# CC2753 register map
File version: 1.0
CPU: CM0+ r0p4, little endian, no MPU, no FPU, VTOR, 3 interrupt priority bits
Registers are 32-bit, read-write, reset 0x0 unless marked. A register's access mark holds for its fields unless they carry their own. Offsets are from the block's base; [hi:lo] are bit positions; {n}, {i} and the like mark numbered series; 'fields as' and 'values as' point back to an identical list.

## RTC — ULL Real Time Clock module RTC includes 2 channels. - Channel 0 is a compare channel - Channel 1 is a capture channel
Base 0x40002000
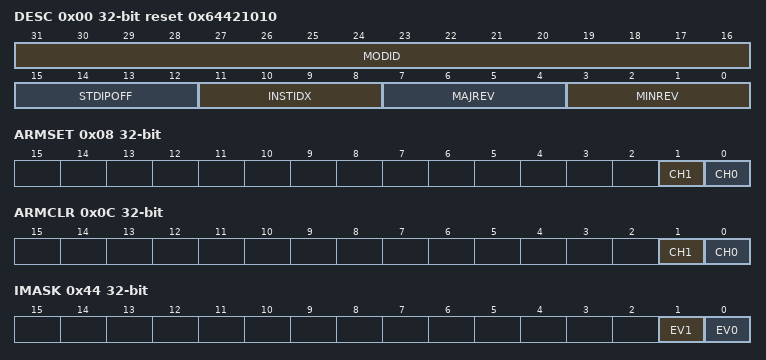
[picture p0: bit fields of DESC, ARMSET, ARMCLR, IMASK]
0x00 DESC ro reset 0x64421010 — Description Register. This register provides IP module ID, revision information, instance index and standard MMR registers offset.
  [31:16] MODID — Module identifier used to uniquely identify this IP.
  [15:12] STDIPOFF — Standard IP MMR block offset. Standard IP MMRs are the set of from aggregated IRQ registers till DTB. 0: Standard IP MMRs do not exist 0x1-0xF: Standard IP MMRs begin at offset of (64*STDIPOFF from the base IP address)
  [11:8] INSTIDX — IP Instance ID number. If multiple instances of IP exist in the device, this field can identify the instance number (0-15).
  [7:4] MAJREV — Major revision of IP (0-15).
  [3:0] MINREV — Minor revision of IP (0-15).
0x04 CTL — RTC Control register. This register controls resetting the of RTC counter
  [0] RST wo — RTC counter reset. Writing 1 to this bit will reset the RTC counter, and cause it to resume counting from 0x0
    1=CLR (Reset the timer.); 0=NOEFF (No effect)
0x08 ARMSET — RTC channel mode set register. Read to each bit field of this register provides the current channel mode. - Read of 1'b0 indicates the channel is unarmed. - Read of 1'b1 indicates the channel is either in capture or compare mode. A write to each bitfield of this register the following effect: - Write of 1'b0 has no effect on channel mode. - Write of 1'b1 has no effect on the compare channel. While write of 1'b1 for capture channel will arm it in capture mode if it is disabled.
  [1] CH1 — Arming Channel 1 for capture operation.
    1=SET (Enable the Channel 1 for capture operation); 0=NOEFF (No effect on the channel)
  [0] CH0 — No effect on arming the channel. Read will give the status of the Channel 0.
    1=SET (No effect on the compare channel); 0=NOEFF (No effect on the channel)
0x0C ARMCLR — RTC channel mode clear register. Read to each bit field of this register provides the current channel mode. - Read of 1'b0 indicates the channel is unarmed. - Read of 1'b1 indicates the channel is either in capture or compare mode. A write to each bitfield of this register the following effect: - Write of 1'b0 has no effect on channel mode. - Write of 1'b1 for capture/compare channel will disarm it without triggering event unless a compare/capture event happens in the same cycle.
  [1] CH1 — Disarming Channel 1
    1=CLR (Set channel in UNARMED state without triggering event unless a capture event happens in the same cycle); 0=NOEFF (No effect on the channel)
  [0] CH0 — Disarming Channel 0
    1=CLR (Set channel in UNARMED state without triggering event unless a compare event happens in the same cycle); 0=NOEFF (No effect on the channel)
0x10 TIME250N ro — RTC Time value register. 32-bit unsigned integer representing [29:-2] time slice of the real time clock counter. The counter runs on LFCLK. This field has a resolution of 250ns, and range of about 17.8 minutes.
  [31:0] VAL — [29:-2] slice of RTC TIME[50:-2]. Slice has an LSB weight of 250 ns and modular range 17m 53.74182002 s. RTC.TIME is updated every LF clock modulo by a fixed or measured LFINC value and will thus on average update only every ~30.5 us. SYSTIM.TIME is synchronized to RTC TIME[31:-2] and is updated every 250 ns if better resolution is needed (in addition to having a much shorter access time of 1-2 cycles instead of 22-26 cycles for RTC.TIMEx).
0x14 TIME1U ro — RTC Time value register. 32-bit unsigned integer representing [31:0] time slice of the real time clock counter. The counter runs on LFCLK. This field has a resolution of 1us, and range of about 1.19 hours.
  [31:0] VAL — [31:0] slice of RTC TIME[50:-2]. Slice has an LSB weight of 1 us and modular range 1h 11m 34.967296s. RTC.TIME is updated every LF clock modulo by a fixed or measured LFINC value and will thus on average update only every ~30.5 us. SYSTIM.TIME is synchronized to RTC TIME[31:-2] and is updated every 250 ns if better resolution is needed (in addition to having a much shorter access time of 1-2 cycles instead of 22-26 cycles for RTC.TIMEx).
0x18 TIME8U ro — RTC Time value register. 32-bit unsigned integer representing [34:3] time slice of the real time clock counter. The counter runs on LFCLK. This field has a resolution of 8us, and range of about 9.5 hours.
  [31:0] VAL — [34:3] slice of RTC TIME[50:-2]. Slice has an LSB weight of 8 us and modular range 9h 32m 39.73836s. RTC.TIME is updated every LF clock modulo by a fixed or measured LFINC value and will thus on average update only every ~30.5 us. SYSTIM.TIME is synchronized to RTC TIME[31:-2] and is updated every 250 ns if better resolution is needed (in addition to having a much shorter access time of 1-2 cycles instead of 22-26 cycles for RTC.TIMEx).
0x1C TIME524M ro — RTC time value register. 32-bit unsigned integer representing [50:19] time slice of the real time clock counter. This field has a resolution of about 0.5s and a range of about 71.4 years.
  [31:0] VAL — [50:19] slice of RTC TIME[50:-2]. Slice has an LSB weight of 0.524288s and modular range of approximately 71 years 147 days 11h 56m 53s. RTC.TIME is updated every LF clock modulo by a fixed or measured LFINC value and will thus on average update only every ~30.5 us. SYSTIM.TIME is synchronized to RTC TIME[31:-2] and is updated every 250 ns if better resolution is needed (in addition to having a much shorter access time of 1-2 cycles instead of 22-26 cycles for RTC.TIMEx).
0x20 CH0CC250N — Channel 0 compare value with 250ns resolution. A read to this register returns the value {CH0CC8U[29:3], 5b’0} A write to this register arms the channel in compare mode. Event would occur at the same time +/ Tlfclk/2 on the RTC as if it was written to SYSTIM.
  [31:0] VAL — RTC Channel 0 compare value. This value is compared against TIME8U.VAL. A Channel 0 event is generated when TIME8U.VAL value reaches or exceeds this compare value.
0x24 CH0CC1U — Channel 0 compare value with 1us resolution. A read to this register returns the value {CH0CC8U[31:3], 3b’0} A write to this register arms the channel in compare mode. Event would occur at the same time +/ Tlfclk/2 on the RTC as if it was written to SYSTIM.
  fields as CH0CC250N
0x28 CH0CC8U — Channel 0 compare value. A write to this register automatically enables the channel to trigger an event when RTC timer reaches the programmed value or if the programmed value is 1 sec in the past.
  fields as CH0CC250N
0x38 CH1CC8U ro — Channel 1 capture value. This register captures the RTC time slice [34:3] on each selected edge of the capture event when the ARMSET.CH1 = 1.
  [20:0] VAL — TIME8U.VAL captured value at the last selected edge of capture event.
0x3C CH1CFG — Channel 1 configuration register. This register can be used to select the capture edge for generating the capture event.
  [0] EDGE — Edge detect configuration for capture source
    1=FALL (Falling Edge.); 0=RISE (Rising Edge.)
0x44 IMASK — Interrupt Mask. If a bit is set, then corresponding interrupt is un-masked. Un-masking the interrupt causes the raw interrupt to be visible in IIDX, as well as MIS.
  [1] EV1 — Channel 1 Event Interrupt Mask.
    1=EN (Enable Interrrupt Mask); 0=DIS (Clear Interrupt Mask)
  [0] EV0 — Channel 0 Event Interrupt Mask.
    1=EN (Enable Interrrupt Mask); 0=DIS (Disable Interrupt Mask)
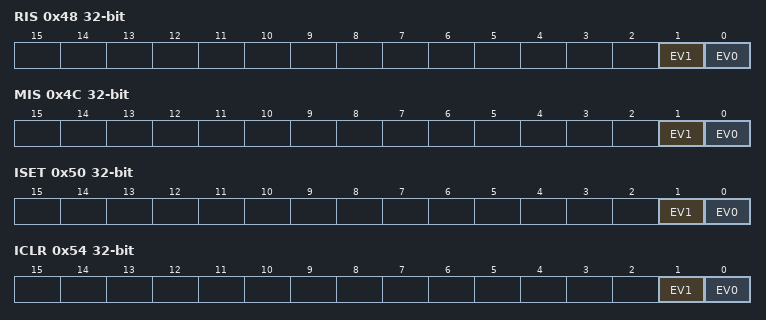
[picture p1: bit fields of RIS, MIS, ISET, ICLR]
0x48 RIS ro — Interrupt mask. This register selects interrupt sources which are allowed to pass from RIS to MIS when the corresponding bit-fields are set to 1.
  [1] EV1 — Raw interrupt status for Channel 1 event. This bit is set to 1 when a capture event is received on Channel 1. This bit will be cleared when the bit in ICLR.EV1 is set to 1 or when the captured time value is read from the CH1CC8U register.
    1=SET (Interrupt occured); 0=CLR (Interrupt did not occur)
  [0] EV0 — Raw interrupt status for Channel 0 event. This bit is set to 1 when a compare event occurs on Channel 0. This bit will be cleared. When the corresponding bit in ICLR.EV0 is set to 1. Or when a new compare value is written in CH0CC8U register
    1=SET (Interrupt occured); 0=CLR (Interrupt did not occur)
0x4C MIS ro — Masked interrupt status. This register is simply a bitwise AND of the contents of IMASK and RIS.*] registers. A flag set in this register can be cleared by writing 1 to the corresponding ICLR register bit.
  [1] EV1 — Masked interrupt status for channel 1 event.
    1=SET (Interrupt occured); 0=CLR (Interrupt did not occur)
  [0] EV0 — Masked interrupt status for channel 0 event.
    1=SET (Interrupt occured); 0=CLR (Interrupt did not occur)
0x50 ISET wo — Interrupt set register. This register can used by software for diagnostics and safety checking purposes. Writing a 1 to a bit in this register will set the event and the corresponding RIS bit also gets set. If the corresponding IMASK bit is set, then the corresponding MIS register bit also gets set.
  [1] EV1 — Set Channel 1 event Interrupt.
    1=SET (Set interrupt); 0=NO_EFFECT (Writing 0 has no effect)
  [0] EV0 — Set Channel 0 event Interrupt.
    1=SET (Set interrupt); 0=NO_EFFECT (Writing 0 has no effect)
0x54 ICLR wo — Interrupt clear register. This register allows software to clear interrupts. Writing a 1 to a bit in this register will clear the event and the corresponding RIS bit also gets cleared. If the corresponding IMASK bit is set, then the corresponding MIS register bit also gets cleared.
  [1] EV1 — Clears channel 1 event interrupt.
    1=CLR (Clear Interrupt); 0=NO_EFF (Writing 0 has no effect)
  [0] EV0 — Clears channel 0 event interrupt.
    1=CLR (Clear Interrupt.); 0=NO_EFF (Writing 0 has no effect)
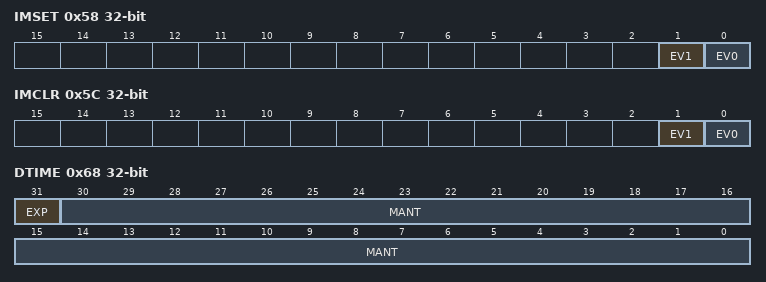
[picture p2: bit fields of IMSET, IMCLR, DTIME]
0x58 IMSET wo — Interrupt mask set register. Writing a 1 to a bit in this register will set the corresponding IMASK bit.
  [1] EV1 — Set channel 1 event interrupt mask.
    1=SET (Set interrupt mask); 0=NO_EFF (Writing 0 has no effect)
  [0] EV0 — Set channel 0 event interrupt mask.
    values as EV1
0x5C IMCLR wo — Interrupt mask clear register. Writing a 1 to a bit in this register will clear the corresponding IMASK bit.
  [1] EV1 — Clears Channel 1 event interrupt mask.
    1=CLR (Clear Interrupt Mask); 0=NO_EFF (Writing 0 has no effect)
  [0] EV0 — Clears Channel 0 event interrupt mask.
    values as EV1
0x60 EMU — Emulation control register. This register controls the behavior of the IP related to core halted input.
  [0] HALT — Halt control.
    1=STOP (Freeze option. The IP freezes functionality when the core halted input is asserted, and resumes when it is deasserted. The freeze can either be immediate or after the IP has reached a boundary from where it can resume without corruption.); 0=RUN (Free run option. The IP ignores the state of the core halted input.)
0x68 DTIME wo — A delta time mechanism is implemented for RTC that allows the TIME value to be adjusted under software control. This is used by boot code to perform the compensation for reset duration (accomplished by adding MMR write to FCFG.generalTrims copylist to avoid ROM changes) TIME[50:-2] is adjusted by TIME += sxt(MANT[30:0], 53) * 2^(22*EXP). In other words: (EXP==0): TIME is adjusted by MANT * 250 ns (range +/-134 s) (EXP==1): TIME is adjusted by MANT * 1.049 s (range +/- 35.7 yr) If used by an application to adjust RTC TIME value, the write to DTIME must occur as quickly as possible after an lftick event. It should also be followed by a write of 1 to SYSTIM.STATUS.SYNCUP to ensure that SYSTIM resynchronizes to the new RTC TIME value at the next lftick event.
  [31] EXP — Exponent
  [30:0] MANT — Mantissa
